# trng: IP-XACT component
VLNV ssd-soc:sec_ss:trng:1.0.0

## Ports
in clk
in rst_n
out irq_o

## Address spaces and blocks
regs.trng_regs: base 0x0, range 4096, width 32, register

## Registers
Registers are 32-bit, read-write, no defined reset value unless marked. A register's access mark holds for its fields unless they carry their own. Offsets are from the block's base; lines under a group give offsets from that group; [hi:lo] are bit positions; {n}, {i} and the like mark numbered series; 'fields as' and 'values as' point back to an identical list; <NAME> marks a mode.

## regs.trng_regs
Base 0x00000000
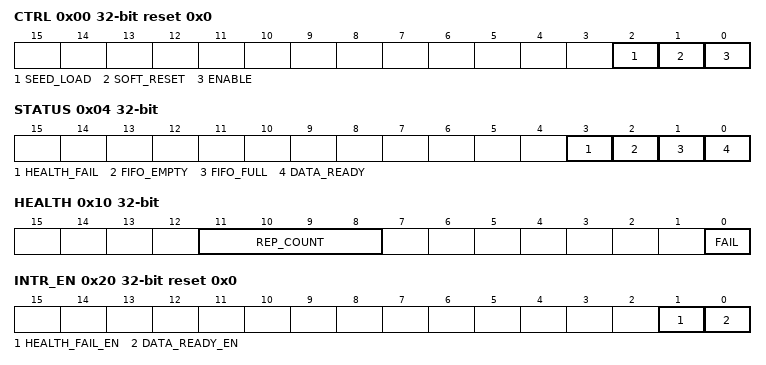
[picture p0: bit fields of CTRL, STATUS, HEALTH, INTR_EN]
0x00 CTRL reset 0x0 — Enable + self-clearing pulses (soft-reset / seed-load).
  [2] SEED_LOAD wo write-1-sets, [1] SOFT_RESET wo write-1-sets, [0] ENABLE
0x04 STATUS ro — Live status bits (read-only).
  [3] HEALTH_FAIL, [2] FIFO_EMPTY, [1] FIFO_FULL, [0] DATA_READY
0x08 DATA ro — Random word output. Read pop 으로 FIFO 한 word 꺼냄.
  [31:0] WORD read-clears
0x0C FIFO_LEVEL ro — 현재 FIFO 에 저장된 word 수 (0..16).
  [4:0] LEVEL
0x10 HEALTH ro — Repetition health test status.
  [11:8] REP_COUNT, [0] FAIL
0x14 SEED0 reset 0x80000001 — LFSR0 seed (SEED_LOAD pulse 시 LFSR 로 로드).
  [31:0] VALUE
0x18 SEED1 reset 0xA5A5A5A5 — LFSR1 seed.
  [31:0] VALUE
0x1C SEED2 reset 0xC3C3C3C3 — LFSR2 seed.
  [31:0] VALUE
0x20 INTR_EN reset 0x0 — Interrupt source enable mask.
  [1] HEALTH_FAIL_EN, [0] DATA_READY_EN
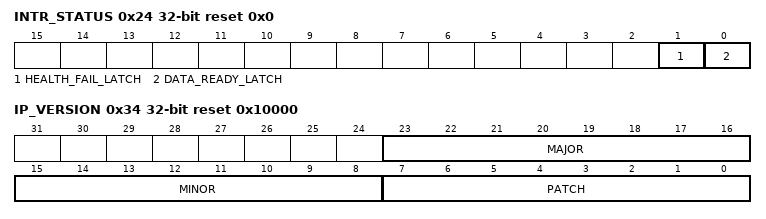
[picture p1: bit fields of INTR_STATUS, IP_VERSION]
0x24 INTR_STATUS reset 0x0 — Edge-latched interrupt status (W1C).
  [1] HEALTH_FAIL_LATCH write-1-clears, [0] DATA_READY_LATCH write-1-clears
0x30 IP_ID ro reset 0x54524E47 — IP 식별자 상수 ("TRNG" = 0x54524E47).
  [31:0] VALUE
0x34 IP_VERSION ro reset 0x10000 — Version 상수: {major[15:8], minor[7:0], patch[7:0]} = 1.0.0.
  [23:16] MAJOR, [15:8] MINOR, [7:0] PATCH
